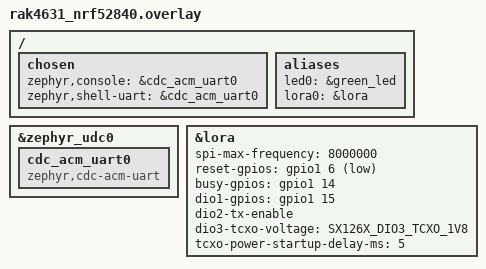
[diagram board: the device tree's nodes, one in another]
/* RAK4631 device tree overlay for LICHEN bridge */

#include <zephyr/dt-bindings/lora/sx126x.h>

/ {
    chosen {
        zephyr,console = &cdc_acm_uart0;
        zephyr,shell-uart = &cdc_acm_uart0;
    };

    aliases {
        led0 = &green_led;
        lora0 = &lora;
    };

};

&zephyr_udc0 {
    cdc_acm_uart0: cdc_acm_uart0 {
        compatible = "zephyr,cdc-acm-uart";
    };
};

/* SX1262 LoRa radio from the upstream RAK4631 board DTS. */
&lora {
    status = "okay";
    spi-max-frequency = <8000000>;
    reset-gpios = <&gpio1 6 GPIO_ACTIVE_LOW>;   /* P1.06 = RST */
    busy-gpios = <&gpio1 14 GPIO_ACTIVE_HIGH>;  /* P1.14 = BUSY */
    dio1-gpios = <&gpio1 15 GPIO_ACTIVE_HIGH>;  /* P1.15 = DIO1 */
    /* DIO2 controls RF switch internally */
    dio2-tx-enable;
    /* 1.8V TCXO controlled by DIO3 */
    dio3-tcxo-voltage = <SX126X_DIO3_TCXO_1V8>;
    tcxo-power-startup-delay-ms = <5>;
};
